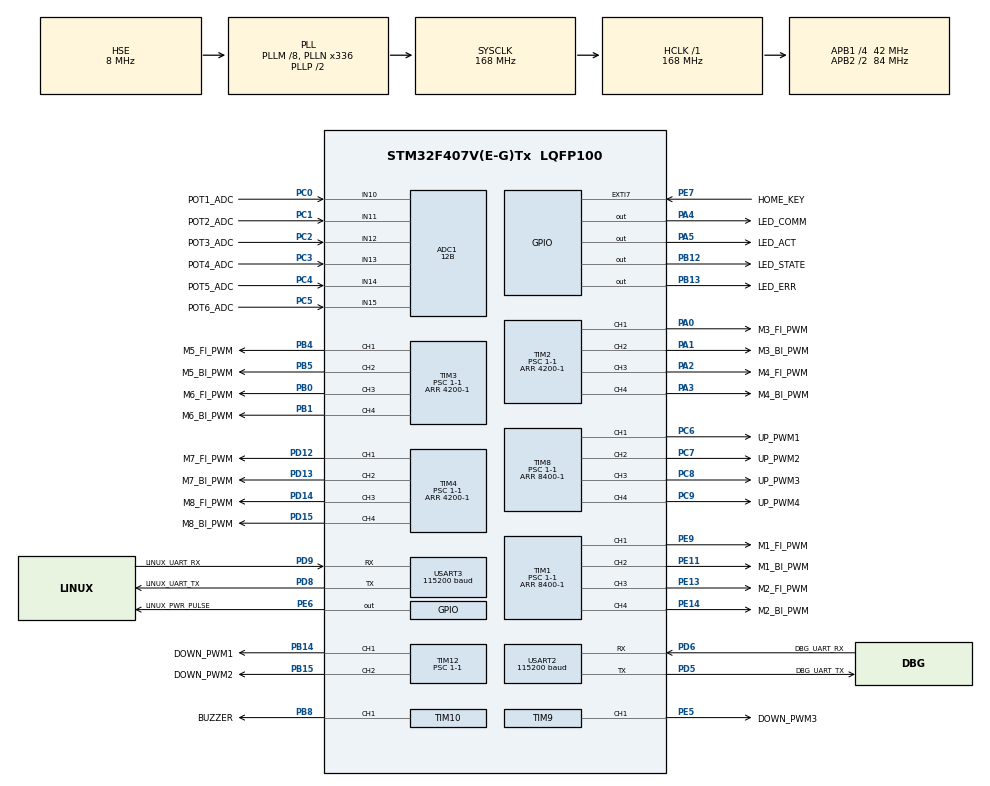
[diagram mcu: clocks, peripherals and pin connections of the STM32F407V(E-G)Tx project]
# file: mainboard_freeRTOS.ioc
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ADC1.Channel-0\#ChannelRegularConversion=ADC_CHANNEL_10
ADC1.Channel-1\#ChannelRegularConversion=ADC_CHANNEL_11
ADC1.Channel-2\#ChannelRegularConversion=ADC_CHANNEL_12
ADC1.Channel-3\#ChannelRegularConversion=ADC_CHANNEL_13
ADC1.Channel-4\#ChannelRegularConversion=ADC_CHANNEL_14
ADC1.Channel-5\#ChannelRegularConversion=ADC_CHANNEL_15
ADC1.ClockPrescaler=ADC_CLOCK_SYNC_PCLK_DIV4
ADC1.ContinuousConvMode=ENABLE
ADC1.DMAContinuousRequests=DISABLE
ADC1.DataAlign=ADC_DATAALIGN_RIGHT
ADC1.DiscontinuousConvMode=DISABLE
ADC1.EOCSelection=ADC_EOC_SEQ_CONV
ADC1.ExternalTrigConvEdge=ADC_EXTERNALTRIGCONVEDGE_NONE
ADC1.NbrOfConversion=6
ADC1.NbrOfConversionFlag=1
ADC1.Rank-0\#ChannelRegularConversion=1
ADC1.Rank-1\#ChannelRegularConversion=2
ADC1.Rank-2\#ChannelRegularConversion=3
ADC1.Rank-3\#ChannelRegularConversion=4
ADC1.Rank-4\#ChannelRegularConversion=5
ADC1.Rank-5\#ChannelRegularConversion=6
ADC1.Resolution=ADC_RESOLUTION_12B
ADC1.SamplingTime-0\#ChannelRegularConversion=ADC_SAMPLETIME_84CYCLES
ADC1.SamplingTime-1\#ChannelRegularConversion=ADC_SAMPLETIME_84CYCLES
ADC1.SamplingTime-2\#ChannelRegularConversion=ADC_SAMPLETIME_84CYCLES
ADC1.SamplingTime-3\#ChannelRegularConversion=ADC_SAMPLETIME_84CYCLES
ADC1.SamplingTime-4\#ChannelRegularConversion=ADC_SAMPLETIME_84CYCLES
ADC1.SamplingTime-5\#ChannelRegularConversion=ADC_SAMPLETIME_84CYCLES
ADC1.ScanConvMode=ENABLE
ADC1.master=1
Mcu.Family=STM32F4
Mcu.Name=STM32F407V(E-G)Tx
Mcu.Package=LQFP100
NVIC.EXTI9_5_IRQn=true\:5\:0\:true\:false\:true\:false\:true\:true
NVIC.PriorityGroup=NVIC_PRIORITYGROUP_4
NVIC.TIM6_DAC_IRQn=true\:15\:0\:false\:false\:true\:false\:true\:true
NVIC.TimeBase=TIM6_DAC_IRQn
NVIC.TimeBaseIP=TIM6
PA0-WKUP.GPIO_Label=M3_FI_PWM
PA0-WKUP.Signal=S_TIM2_CH1_ETR
PA1.GPIO_Label=M3_BI_PWM
PA1.Signal=S_TIM2_CH2
PA13.Mode=Serial_Wire
PA13.Signal=SYS_JTMS-SWDIO
PA14.Mode=Serial_Wire
PA14.Signal=SYS_JTCK-SWCLK
PA2.GPIO_Label=M4_FI_PWM
PA2.Signal=S_TIM2_CH3
PA3.GPIO_Label=M4_BI_PWM
PA3.Signal=S_TIM2_CH4
PA4.GPIO_Label=LED_COMM
PA4.PinState=GPIO_PIN_SET
PA4.Signal=GPIO_Output
PA5.GPIO_Label=LED_ACT
PA5.PinState=GPIO_PIN_SET
PA5.Signal=GPIO_Output
PB0.GPIO_Label=M6_FI_PWM
PB0.Signal=S_TIM3_CH3
PB1.GPIO_Label=M6_BI_PWM
PB1.Signal=S_TIM3_CH4
PB12.GPIO_Label=LED_STATE
PB12.PinState=GPIO_PIN_SET
PB12.Signal=GPIO_Output
PB13.GPIO_Label=LED_ERR
PB13.PinState=GPIO_PIN_SET
PB13.Signal=GPIO_Output
PB14.GPIO_Label=DOWN_PWM1
PB14.Signal=S_TIM12_CH1
PB15.GPIO_Label=DOWN_PWM2
PB15.Signal=S_TIM12_CH2
PB4.GPIO_Label=M5_FI_PWM
PB4.Signal=S_TIM3_CH1
PB5.GPIO_Label=M5_BI_PWM
PB5.Signal=S_TIM3_CH2
PB8.GPIO_Label=BUZZER
PB8.Signal=S_TIM10_CH1
PC0.GPIO_Label=POT1_ADC
PC0.Signal=ADCx_IN10
PC1.GPIO_Label=POT2_ADC
PC1.Signal=ADCx_IN11
PC14-OSC32_IN.Mode=LSE-External-Oscillator
PC14-OSC32_IN.Signal=RCC_OSC32_IN
PC15-OSC32_OUT.Mode=LSE-External-Oscillator
PC15-OSC32_OUT.Signal=RCC_OSC32_OUT
PC2.GPIO_Label=POT3_ADC
PC2.Signal=ADCx_IN12
PC3.GPIO_Label=POT4_ADC
PC3.Signal=ADCx_IN13
PC4.GPIO_Label=POT5_ADC
PC4.Signal=ADCx_IN14
PC5.GPIO_Label=POT6_ADC
PC5.Signal=ADCx_IN15
PC6.GPIO_Label=UP_PWM1
PC6.Signal=S_TIM8_CH1
PC7.GPIO_Label=UP_PWM2
PC7.Signal=S_TIM8_CH2
PC8.GPIO_Label=UP_PWM3
PC8.Signal=S_TIM8_CH3
PC9.GPIO_Label=UP_PWM4
PC9.Signal=S_TIM8_CH4
PD12.GPIO_Label=M7_FI_PWM
PD12.Signal=S_TIM4_CH1
PD13.GPIO_Label=M7_BI_PWM
PD13.Signal=S_TIM4_CH2
PD14.GPIO_Label=M8_FI_PWM
PD14.Signal=S_TIM4_CH3
PD15.GPIO_Label=M8_BI_PWM
PD15.Signal=S_TIM4_CH4
PD5.GPIO_Label=DBG_UART_TX
PD5.Mode=Asynchronous
PD5.Signal=USART2_TX
PD6.GPIO_Label=DBG_UART_RX
PD6.Mode=Asynchronous
PD6.Signal=USART2_RX
PD8.GPIO_Label=LINUX_UART_TX
PD8.Mode=Asynchronous
PD8.Signal=USART3_TX
PD9.GPIO_Label=LINUX_UART_RX
PD9.Mode=Asynchronous
PD9.Signal=USART3_RX
PE11.GPIO_Label=M1_BI_PWM
PE11.Signal=S_TIM1_CH2
PE13.GPIO_Label=M2_FI_PWM
PE13.Signal=S_TIM1_CH3
PE14.GPIO_Label=M2_BI_PWM
PE14.Signal=S_TIM1_CH4
PE5.GPIO_Label=DOWN_PWM3
PE5.Signal=S_TIM9_CH1
PE6.GPIO_Label=LINUX_PWR_PULSE
PE6.PinState=GPIO_PIN_SET
PE6.Signal=GPIO_Output
PE7.GPIO_Label=HOME_KEY
PE7.GPIO_ModeDefaultEXTI=GPIO_MODE_IT_FALLING
PE7.Signal=GPXTI7
PE9.GPIO_Label=M1_FI_PWM
PE9.Signal=S_TIM1_CH1
PH0-OSC_IN.Mode=HSE-External-Oscillator
PH0-OSC_IN.Signal=RCC_OSC_IN
PH1-OSC_OUT.Mode=HSE-External-Oscillator
PH1-OSC_OUT.Signal=RCC_OSC_OUT
ProjectManager.HeapSize=0x400
ProjectManager.StackSize=0x800
ProjectManager.TargetToolchain=CMake
RCC.48MHZClocksFreq_Value=48000000
RCC.AHBFreq_Value=168000000
RCC.APB1CLKDivider=RCC_HCLK_DIV4
RCC.APB1Freq_Value=42000000
RCC.APB1TimFreq_Value=84000000
RCC.APB2CLKDivider=RCC_HCLK_DIV2
RCC.APB2Freq_Value=84000000
RCC.APB2TimFreq_Value=168000000
RCC.CortexFreq_Value=168000000
RCC.HCLKFreq_Value=168000000
RCC.HSE_VALUE=8000000
RCC.HSI_VALUE=16000000
RCC.PLLM=8
RCC.PLLN=336
RCC.PLLQ=7
RCC.PLLSourceVirtual=RCC_PLLSOURCE_HSE
RCC.SYSCLKFreq_VALUE=168000000
RCC.SYSCLKSource=RCC_SYSCLKSOURCE_PLLCLK
RCC.VCOOutputFreq_Value=336000000
SH.ADCx_IN10.0=ADC1_IN10,IN10
SH.ADCx_IN11.0=ADC1_IN11,IN11
SH.ADCx_IN12.0=ADC1_IN12,IN12
SH.ADCx_IN13.0=ADC1_IN13,IN13
SH.ADCx_IN14.0=ADC1_IN14,IN14
SH.ADCx_IN15.0=ADC1_IN15,IN15
SH.S_TIM10_CH1.0=TIM10_CH1,PWM Generation1 CH1
SH.S_TIM12_CH1.0=TIM12_CH1,PWM Generation1 CH1
SH.S_TIM12_CH2.0=TIM12_CH2,PWM Generation2 CH2
SH.S_TIM1_CH1.0=TIM1_CH1,PWM Generation1 CH1
SH.S_TIM1_CH2.0=TIM1_CH2,PWM Generation2 CH2
SH.S_TIM1_CH3.0=TIM1_CH3,PWM Generation3 CH3
SH.S_TIM1_CH4.0=TIM1_CH4,PWM Generation4 CH4
SH.S_TIM2_CH1_ETR.0=TIM2_CH1,PWM Generation1 CH1
SH.S_TIM2_CH2.0=TIM2_CH2,PWM Generation2 CH2
SH.S_TIM2_CH3.0=TIM2_CH3,PWM Generation3 CH3
SH.S_TIM2_CH4.0=TIM2_CH4,PWM Generation4 CH4
SH.S_TIM3_CH1.0=TIM3_CH1,PWM Generation1 CH1
SH.S_TIM3_CH2.0=TIM3_CH2,PWM Generation2 CH2
SH.S_TIM3_CH3.0=TIM3_CH3,PWM Generation3 CH3
SH.S_TIM3_CH4.0=TIM3_CH4,PWM Generation4 CH4
SH.S_TIM4_CH1.0=TIM4_CH1,PWM Generation1 CH1
SH.S_TIM4_CH2.0=TIM4_CH2,PWM Generation2 CH2
SH.S_TIM4_CH3.0=TIM4_CH3,PWM Generation3 CH3
SH.S_TIM4_CH4.0=TIM4_CH4,PWM Generation4 CH4
SH.S_TIM8_CH1.0=TIM8_CH1,PWM Generation1 CH1
SH.S_TIM8_CH2.0=TIM8_CH2,PWM Generation2 CH2
SH.S_TIM8_CH3.0=TIM8_CH3,PWM Generation3 CH3
SH.S_TIM8_CH4.0=TIM8_CH4,PWM Generation4 CH4
SH.S_TIM9_CH1.0=TIM9_CH1,PWM Generation1 CH1
TIM1.AutoReloadPreload=TIM_AUTORELOAD_PRELOAD_ENABLE
TIM1.Channel-PWM\ Generation1\ CH1=TIM_CHANNEL_1
TIM1.Channel-PWM\ Generation2\ CH2=TIM_CHANNEL_2
TIM1.Channel-PWM\ Generation3\ CH3=TIM_CHANNEL_3
TIM1.Channel-PWM\ Generation4\ CH4=TIM_CHANNEL_4
TIM1.Period=8400-1
TIM1.Prescaler=1-1
TIM10.AutoReloadPreload=TIM_AUTORELOAD_PRELOAD_ENABLE
TIM10.Channel=TIM_CHANNEL_1
TIM10.Period=62222-1
TIM10.Prescaler=1-1
TIM12.AutoReloadPreload=TIM_AUTORELOAD_PRELOAD_ENABLE
TIM12.Channel-PWM\ Generation1\ CH1=TIM_CHANNEL_1
TIM12.Channel-PWM\ Generation2\ CH2=TIM_CHANNEL_2
TIM12.Period=4200-1
TIM12.Prescaler=1-1
TIM2.AutoReloadPreload=TIM_AUTORELOAD_PRELOAD_ENABLE
TIM2.Channel-PWM\ Generation1\ CH1=TIM_CHANNEL_1
TIM2.Channel-PWM\ Generation2\ CH2=TIM_CHANNEL_2
TIM2.Channel-PWM\ Generation3\ CH3=TIM_CHANNEL_3
TIM2.Channel-PWM\ Generation4\ CH4=TIM_CHANNEL_4
TIM2.Period=4200-1
TIM2.Prescaler=1-1
TIM3.AutoReloadPreload=TIM_AUTORELOAD_PRELOAD_ENABLE
TIM3.Channel-PWM\ Generation1\ CH1=TIM_CHANNEL_1
TIM3.Channel-PWM\ Generation2\ CH2=TIM_CHANNEL_2
TIM3.Channel-PWM\ Generation3\ CH3=TIM_CHANNEL_3
TIM3.Channel-PWM\ Generation4\ CH4=TIM_CHANNEL_4
TIM3.Period=4200-1
TIM3.Prescaler=1-1
TIM4.AutoReloadPreload=TIM_AUTORELOAD_PRELOAD_ENABLE
TIM4.Channel-PWM\ Generation1\ CH1=TIM_CHANNEL_1
TIM4.Channel-PWM\ Generation2\ CH2=TIM_CHANNEL_2
TIM4.Channel-PWM\ Generation3\ CH3=TIM_CHANNEL_3
TIM4.Channel-PWM\ Generation4\ CH4=TIM_CHANNEL_4
TIM4.Period=4200-1
TIM4.Prescaler=1-1
TIM8.AutoReloadPreload=TIM_AUTORELOAD_PRELOAD_ENABLE
TIM8.Channel-PWM\ Generation1\ CH1=TIM_CHANNEL_1
TIM8.Channel-PWM\ Generation2\ CH2=TIM_CHANNEL_2
TIM8.Channel-PWM\ Generation3\ CH3=TIM_CHANNEL_3
TIM8.Channel-PWM\ Generation4\ CH4=TIM_CHANNEL_4
TIM8.Period=8400-1
TIM8.Prescaler=1-1
TIM9.AutoReloadPreload=TIM_AUTORELOAD_PRELOAD_ENABLE
TIM9.Channel-PWM\ Generation1\ CH1=TIM_CHANNEL_1
TIM9.Period=8400-1
TIM9.Prescaler=1-1
USART2.BaudRate=115200
USART2.VirtualMode=VM_ASYNC
USART3.BaudRate=115200
USART3.VirtualMode=VM_ASYNC
VP_SYS_VS_tim6.Mode=TIM6
VP_TIM10_VS_ClockSourceINT.Mode=Enable_Timer
VP_TIM12_VS_ClockSourceINT.Mode=Internal
VP_TIM1_VS_ClockSourceINT.Mode=Internal
VP_TIM2_VS_ClockSourceINT.Mode=Internal
VP_TIM3_VS_ClockSourceINT.Mode=Internal
VP_TIM4_VS_ClockSourceINT.Mode=Internal
VP_TIM8_VS_ClockSourceINT.Mode=Internal
VP_TIM9_VS_ClockSourceINT.Mode=Internal
board=custom

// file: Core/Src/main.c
/* USER CODE BEGIN Header */
/**
 ******************************************************************************
 * @file           : main.c
 * @brief          : Main program body
 ******************************************************************************
 * @attention
 *
 * Copyright (c) 2026 STMicroelectronics.
 * All rights reserved.
 *
 * This software is licensed under terms that can be found in the LICENSE file
 * in the root directory of this software component.
 * If no LICENSE file comes with this software, it is provided AS-IS.
 *
 ******************************************************************************
 */
/* USER CODE END Header */
#include "main.h"
#include "adc.h"
#include "tim.h"
#include "usart.h"
#include "gpio.h"

/* USER CODE BEGIN Includes */
#include "FreeRTOS.h"
#include "task.h"
/* USER CODE END Includes */

void SystemClock_Config(void);
/* USER CODE BEGIN PFP */
void vLED1Task(void *pvParameters);
/* USER CODE END PFP */

int main(void)
{

  /* MCU Configuration--------------------------------------------------------*/

  /* Reset of all peripherals, Initializes the Flash interface and the Systick. */
  HAL_Init();

  /* Configure the system clock */
  SystemClock_Config();

  /* Initialize all configured peripherals */
  MX_GPIO_Init();
  MX_ADC1_Init();
  MX_TIM1_Init();
  MX_TIM2_Init();
  MX_TIM3_Init();
  MX_TIM4_Init();
  MX_TIM8_Init();
  MX_TIM9_Init();
  MX_TIM10_Init();
  MX_TIM12_Init();
  MX_USART2_UART_Init();
  MX_USART3_UART_Init();

  /* Infinite loop */
    while (1)
    {

    }
}

void SystemClock_Config(void)
{
  RCC_OscInitTypeDef RCC_OscInitStruct = {0};
  RCC_ClkInitTypeDef RCC_ClkInitStruct = {0};

  /** Configure the main internal regulator output voltage
  */
  __HAL_RCC_PWR_CLK_ENABLE();
  __HAL_PWR_VOLTAGESCALING_CONFIG(PWR_REGULATOR_VOLTAGE_SCALE1);

  /** Initializes the RCC Oscillators according to the specified parameters
  * in the RCC_OscInitTypeDef structure.
  */
  RCC_OscInitStruct.OscillatorType = RCC_OSCILLATORTYPE_HSE;
  RCC_OscInitStruct.HSEState = RCC_HSE_ON;
  RCC_OscInitStruct.PLL.PLLState = RCC_PLL_ON;
  RCC_OscInitStruct.PLL.PLLSource = RCC_PLLSOURCE_HSE;
  RCC_OscInitStruct.PLL.PLLM = 8;
  RCC_OscInitStruct.PLL.PLLN = 336;
  RCC_OscInitStruct.PLL.PLLP = RCC_PLLP_DIV2;
  RCC_OscInitStruct.PLL.PLLQ = 7;
  if (HAL_RCC_OscConfig(&RCC_OscInitStruct) != HAL_OK)
  {
    Error_Handler();
  }

  /** Initializes the CPU, AHB and APB buses clocks
  */
  RCC_ClkInitStruct.ClockType = RCC_CLOCKTYPE_HCLK|RCC_CLOCKTYPE_SYSCLK
                              |RCC_CLOCKTYPE_PCLK1|RCC_CLOCKTYPE_PCLK2;
  RCC_ClkInitStruct.SYSCLKSource = RCC_SYSCLKSOURCE_PLLCLK;
  RCC_ClkInitStruct.AHBCLKDivider = RCC_SYSCLK_DIV1;
  RCC_ClkInitStruct.APB1CLKDivider = RCC_HCLK_DIV4;
  RCC_ClkInitStruct.APB2CLKDivider = RCC_HCLK_DIV2;

  if (HAL_RCC_ClockConfig(&RCC_ClkInitStruct, FLASH_LATENCY_5) != HAL_OK)
  {
    Error_Handler();
  }
}

void HAL_TIM_PeriodElapsedCallback(TIM_HandleTypeDef *htim)
{
  if (htim->Instance == TIM6)
  {
    HAL_IncTick();
  }
}

void Error_Handler(void)
{
  /* USER CODE BEGIN Error_Handler_Debug */
    /* User can add his own implementation to report the HAL error return state
     */
    __disable_irq();
    while (1)
    {
    }
  /* USER CODE END Error_Handler_Debug */
}
#ifdef USE_FULL_ASSERT
/**
  * @brief  Reports the name of the source file and the source line number
  *         where the assert_param error has occurred.
  * @param  file: pointer to the source file name
  * @param  line: assert_param error line source number
  * @retval None
  */
void assert_failed(uint8_t *file, uint32_t line)
{
  /* USER CODE BEGIN 6 */
    /* User can add his own implementation to report the file name and line
       number, ex: printf("Wrong parameters value: file %s on line %d\r\n",
       file, line) */
  /* USER CODE END 6 */
}
#endif /* USE_FULL_ASSERT */
